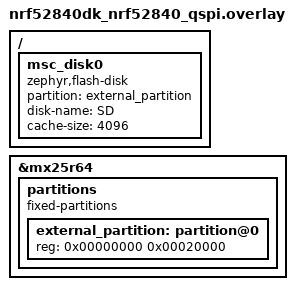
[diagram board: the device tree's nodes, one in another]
/*
 * Copyright (c) 2023 Nordic Semiconductor ASA
 *
 * SPDX-License-Identifier: Apache-2.0
 */

/* Note that default partition layout, provided by board DTS, is not
 * altered here as external_partition used by the disk is defined
 * over QSPI device and does not collide with any other partition
 * definition.
 */

&mx25r64 {
	partitions {
		compatible = "fixed-partitions";
		#address-cells = <1>;
		#size-cells = <1>;

		/* 128kiB external storage partition */
		external_partition: partition@0 {
			reg = <0x00000000 0x00020000>;
		};
	};
};

/ {
	msc_disk0 {
		status="okay";
		compatible = "zephyr,flash-disk";
		partition = <&external_partition>;
		disk-name = "SD";
		/* cache-size == page erase size */
		cache-size = <4096>;
	};
};
